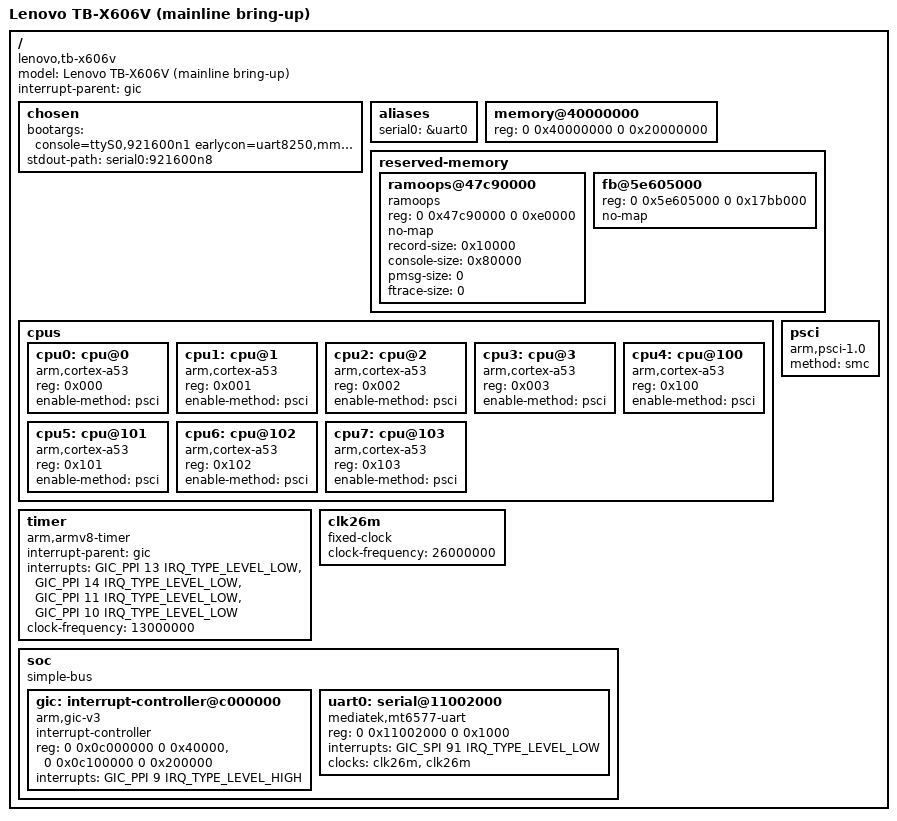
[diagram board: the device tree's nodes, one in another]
// SPDX-License-Identifier: GPL-2.0
/* Minimal bring-up tree for the Lenovo TB-X606V (MT6765/MT8768), values copied from the vendor mt6765.dts.
 * Goal: reach userspace on a mainline kernel and leave a console log in the pstore RAM area. No display, no USB. */
/dts-v1/;
#include <dt-bindings/interrupt-controller/arm-gic.h>
#include <dt-bindings/interrupt-controller/irq.h>

/ {
	model = "Lenovo TB-X606V (mainline bring-up)";
	compatible = "lenovo,tb-x606v", "mediatek,mt6765";
	interrupt-parent = <&gic>;
	#address-cells = <2>;
	#size-cells = <2>;

	chosen {
		bootargs = "console=ttyS0,921600n1 earlycon=uart8250,mmio32,0x11002000 rdinit=/init panic=10 loglevel=8 printk.time=1 ignore_loglevel";
		stdout-path = "serial0:921600n8";
	};

	aliases { serial0 = &uart0; };

	memory@40000000 {
		device_type = "memory";
		reg = <0 0x40000000 0 0x20000000>;
	};

	reserved-memory {
		#address-cells = <2>;
		#size-cells = <2>;
		ranges;

		ramoops@47c90000 {
			compatible = "ramoops";
			reg = <0 0x47c90000 0 0xe0000>;
			no-map;
			record-size = <0x10000>;
			console-size = <0x80000>;
			pmsg-size = <0>;
			ftrace-size = <0>;
		};

		fb@5e605000 {
			reg = <0 0x5e605000 0 0x17bb000>;
			no-map;
		};
	};

	cpus {
		#address-cells = <1>;
		#size-cells = <0>;
		cpu0: cpu@0   { device_type = "cpu"; compatible = "arm,cortex-a53"; reg = <0x000>; enable-method = "psci"; };
		cpu1: cpu@1   { device_type = "cpu"; compatible = "arm,cortex-a53"; reg = <0x001>; enable-method = "psci"; };
		cpu2: cpu@2   { device_type = "cpu"; compatible = "arm,cortex-a53"; reg = <0x002>; enable-method = "psci"; };
		cpu3: cpu@3   { device_type = "cpu"; compatible = "arm,cortex-a53"; reg = <0x003>; enable-method = "psci"; };
		cpu4: cpu@100 { device_type = "cpu"; compatible = "arm,cortex-a53"; reg = <0x100>; enable-method = "psci"; };
		cpu5: cpu@101 { device_type = "cpu"; compatible = "arm,cortex-a53"; reg = <0x101>; enable-method = "psci"; };
		cpu6: cpu@102 { device_type = "cpu"; compatible = "arm,cortex-a53"; reg = <0x102>; enable-method = "psci"; };
		cpu7: cpu@103 { device_type = "cpu"; compatible = "arm,cortex-a53"; reg = <0x103>; enable-method = "psci"; };
	};

	psci {
		compatible = "arm,psci-1.0";
		method = "smc";
	};

	timer {
		compatible = "arm,armv8-timer";
		interrupt-parent = <&gic>;
		interrupts = <GIC_PPI 13 IRQ_TYPE_LEVEL_LOW>,
			     <GIC_PPI 14 IRQ_TYPE_LEVEL_LOW>,
			     <GIC_PPI 11 IRQ_TYPE_LEVEL_LOW>,
			     <GIC_PPI 10 IRQ_TYPE_LEVEL_LOW>;
		clock-frequency = <13000000>;
	};

	clk26m: clk26m {
		compatible = "fixed-clock";
		#clock-cells = <0>;
		clock-frequency = <26000000>;
	};

	soc {
		compatible = "simple-bus";
		#address-cells = <2>;
		#size-cells = <2>;
		ranges;

		gic: interrupt-controller@c000000 {
			compatible = "arm,gic-v3";
			#interrupt-cells = <3>;
			interrupt-controller;
			reg = <0 0x0c000000 0 0x40000>, <0 0x0c100000 0 0x200000>;
			interrupts = <GIC_PPI 9 IRQ_TYPE_LEVEL_HIGH>;
		};

		uart0: serial@11002000 {
			compatible = "mediatek,mt6577-uart";
			reg = <0 0x11002000 0 0x1000>;
			interrupts = <GIC_SPI 91 IRQ_TYPE_LEVEL_LOW>;
			clocks = <&clk26m>, <&clk26m>;
			clock-names = "baud", "bus";
		};
	};
};
